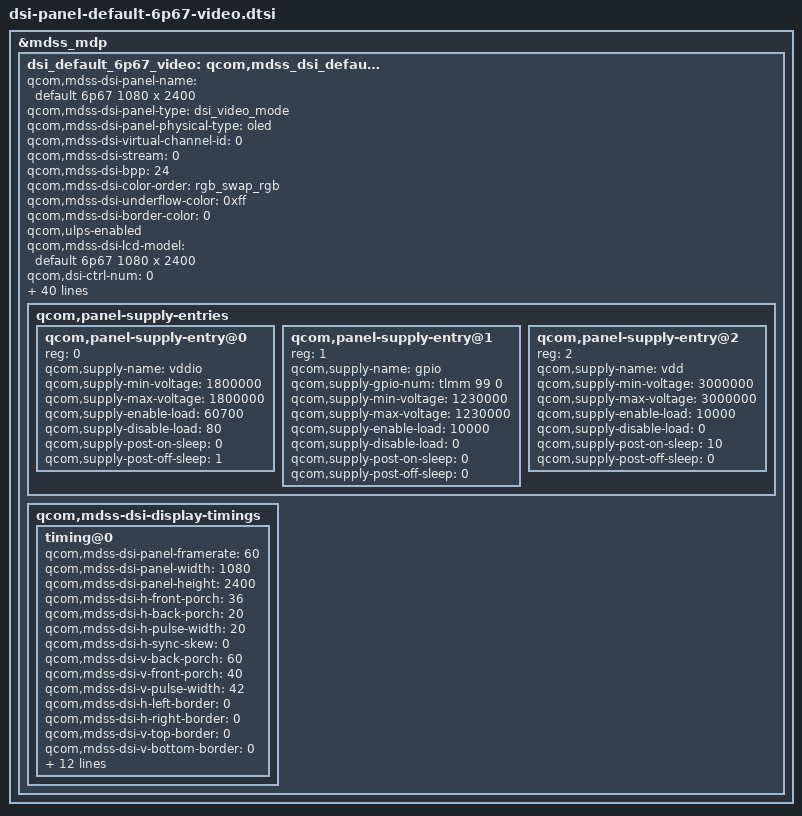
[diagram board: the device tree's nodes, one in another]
&mdss_mdp {
	dsi_default_6p67_video: qcom,mdss_dsi_default_6p67_video {
		qcom,mdss-dsi-panel-name =
			"default 6p67 1080 x 2400";
		qcom,mdss-dsi-panel-type = "dsi_video_mode";
		qcom,mdss-dsi-panel-physical-type = "oled";
		qcom,mdss-dsi-virtual-channel-id = <0>;
		qcom,mdss-dsi-stream = <0>;
		qcom,mdss-dsi-bpp = <24>;
		qcom,mdss-dsi-color-order = "rgb_swap_rgb";
		qcom,mdss-dsi-underflow-color = <0xff>;
		qcom,mdss-dsi-border-color = <0>;
		qcom,ulps-enabled;
		qcom,mdss-dsi-lcd-model = "default 6p67 1080 x 2400";

		/* mipi dsi setting */
		qcom,dsi-ctrl-num = <0>;
		qcom,dsi-phy-num = <0>;
		qcom,dsi-sec-ctrl-num = <1>;
		qcom,dsi-sec-phy-num = <1>;
		qcom,mdss-dsi-traffic-mode = "non_burst_sync_event";
		qcom,mdss-dsi-lane-map = "lane_map_0123";
		qcom,mdss-dsi-bllp-eof-power-mode;
		qcom,mdss-dsi-bllp-power-mode;
		qcom,mdss-dsi-lane-0-state;
		qcom,mdss-dsi-lane-1-state;
		qcom,mdss-dsi-lane-2-state;
		qcom,mdss-dsi-lane-3-state;
		qcom,mdss-dsi-dma-trigger = "trigger_sw";
		qcom,mdss-dsi-mdp-trigger = "none";
		qcom,dsi-select-clocks = "mux_byte_clk0", "mux_pixel_clk0";
		qcom,dsi-select-sec-clocks = "mux_byte_clk1", "mux_pixel_clk1";

		/* TE setting */
		qcom,mdss-dsi-te-pin-select = <1>;
		qcom,mdss-dsi-wr-mem-start = <0x2c>;
		qcom,mdss-dsi-wr-mem-continue = <0x3c>;
		qcom,mdss-dsi-te-dcs-command = <1>;
		qcom,mdss-dsi-te-check-enable;
		qcom,mdss-dsi-te-using-te-pin;

		/* hdr setting */
		qcom,mdss-dsi-panel-hdr-color-primaries = <14500 15500 32000
			17000 15500 30000 8000 3000>;
		qcom,mdss-dsi-panel-peak-brightness = <4200000>;
		qcom,mdss-dsi-panel-blackness-level = <3230>;

		/* gpio setting */
		qcom,dsi-panel-gpio-address = <0x0F100000 0x1000>;
		qcom,dsi-panel-gpio-pins = <44 99>;
		qcom,dsi-panel-gpio-names = "reset-gpio", "vdd-gpio";

		/* backlight setting */
		qcom,mdss-dsi-bl-pmic-control-type = "bl_ctrl_dcs";
		qcom,mdss-dsi-bl-min-level = <1>;
		qcom,mdss-dsi-bl-max-level = <4095>;
		qcom,mdss-brightness-max-level = <255>;
		qcom,mdss-dsi-bl-inverted-dbv;

		/* power on/off timing setting */
		qcom,platform-reset-gpio = <&tlmm 44 0>;
		qcom,mdss-dsi-reset-sequence = <1 1>, <0 1>, <1 10>;
		qcom,panel-supply-entries {
			qcom,panel-supply-entry@0 {
					reg = <0>;
					qcom,supply-name = "vddio";
					qcom,supply-min-voltage = <1800000>;
					qcom,supply-max-voltage = <1800000>;
					qcom,supply-enable-load = <60700>;
					qcom,supply-disable-load = <80>;
					qcom,supply-post-on-sleep = <0>;
					qcom,supply-post-off-sleep = <1>;
			};

			qcom,panel-supply-entry@1 {
					reg = <1>;
					qcom,supply-name = "gpio";
					qcom,supply-gpio-num = <&tlmm 99 0>;
					qcom,supply-min-voltage = <1230000>;
					qcom,supply-max-voltage = <1230000>;
					qcom,supply-enable-load = <10000>;
					qcom,supply-disable-load = <0>;
					qcom,supply-post-on-sleep = <0>;
					qcom,supply-post-off-sleep = <0>;
			};

			qcom,panel-supply-entry@2 {
					reg = <2>;
					qcom,supply-name = "vdd";
					qcom,supply-min-voltage = <3000000>;
					qcom,supply-max-voltage = <3000000>;
					qcom,supply-enable-load = <10000>;
					qcom,supply-disable-load = <0>;
					qcom,supply-post-on-sleep = <10>;
					qcom,supply-post-off-sleep = <0>;
			};
		};
		/* display timing0 */
		qcom,mdss-dsi-display-timings {
			timing@0 {
				qcom,mdss-dsi-panel-framerate = <60>;
				qcom,mdss-dsi-panel-width = <1080>;
				qcom,mdss-dsi-panel-height = <2400>;
				qcom,mdss-dsi-h-front-porch = <36>;
				qcom,mdss-dsi-h-back-porch = <20>;
				qcom,mdss-dsi-h-pulse-width = <20>;
				qcom,mdss-dsi-h-sync-skew = <0>;
				qcom,mdss-dsi-v-back-porch = <60>;
				qcom,mdss-dsi-v-front-porch = <40>;
				qcom,mdss-dsi-v-pulse-width = <42>;
				qcom,mdss-dsi-h-left-border = <0>;
				qcom,mdss-dsi-h-right-border = <0>;
				qcom,mdss-dsi-v-top-border = <0>;
				qcom,mdss-dsi-v-bottom-border = <0>;
				qcom,mdss-dsi-panel-jitter = <0x4 0x1>;

				qcom,mdss-dsi-on-command = [
					39 01 00 00 0a 00 06 F0 55 AA 52 00 00
					39 01 00 00 0a 00 05 FF AA 55 A5 80
					39 01 00 00 0a 00 05 FF AA 55 A5 81
					39 01 00 00 0a 00 05 FF AA 55 A5 00
					39 01 00 00 0a 00 06 F0 55 AA 52 08 00
					39 01 00 00 0a 00 05 BE 0E 09 14 13
					39 01 00 00 0a 00 06 F0 55 AA 52 08 01
					39 01 00 00 0a 00 04 D1 07 02 18
					05 01 00 00 0a 00 01 35
					39 01 00 00 0a 00 05 3B 00 10 00 10
					39 01 00 00 0a 00 02 53 20
					39 01 00 00 0a 00 05 51 0D BB 0F FE
					39 01 00 00 0a 00 05 2A 00 00 04 D3
					39 01 00 00 0a 00 05 2B 00 00 0A 73
					39 01 00 00 0a 00 13 91 89 28 00 0C C2 00 03 6A 01 8E 00 11 08 BB 03 B4 10 F0
					39 01 00 00 0a 00 02 90 01
					39 01 00 00 0a 00 02 03 01
					05 01 00 00 0a 00 01 2C
					39 01 00 00 0a 00 02 2F 01
					05 01 00 00 46 00 01 11
					05 01 00 00 0a 00 01 29
				];

				qcom,mdss-dsi-off-command = [
					05 01 00 00 14 00 01 28
					05 01 00 00 78 00 01 10
				];
				qcom,mdss-dsi-on-command-state = "dsi_lp_mode";
				qcom,mdss-dsi-off-command-state = "dsi_hs_mode";
				qcom,mdss-dsi-h-sync-pulse = <0>;
				qcom,mdss-dsi-panel-phy-timings = [00 13 05 04 13 1e 05
						05 05 06 02 04 12 09];
				qcom,display-topology = <1 0 1>;
				qcom,default-topology-index = <0>;
			};
		};
	};
};
